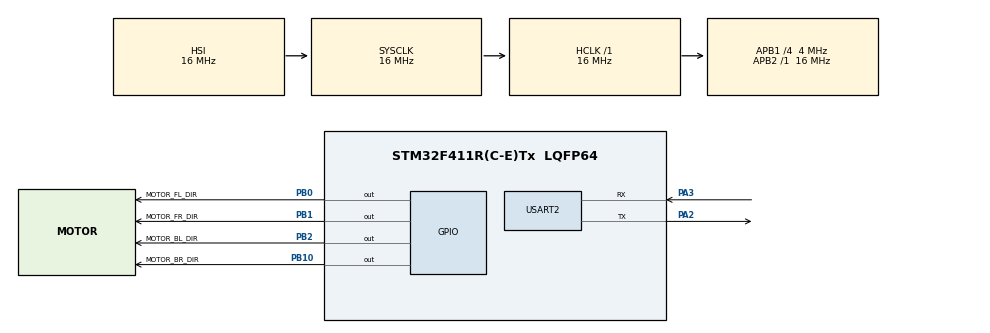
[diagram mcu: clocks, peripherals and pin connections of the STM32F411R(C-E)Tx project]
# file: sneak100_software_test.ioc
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Mcu.Family=STM32F4
RCC.CortexFreq_Value=16000000
PB0.GPIO_Label=MOTOR_FL_DIR
RCC.APB1CLKDivider=RCC_HCLK_DIV4
ProjectManager.StackSize=0x400
PA13.Signal=SYS_JTMS-SWDIO
PA3.Mode=Asynchronous
ProjectManager.TargetToolchain=STM32CubeIDE
PB10.GPIO_Label=MOTOR_BR_DIR
RCC.HCLKFreq_Value=16000000
RCC.APB2TimFreq_Value=16000000
RCC.LSE_VALUE=32768
RCC.AHBFreq_Value=16000000
PB10.Signal=GPIO_Output
RCC.HSE_VALUE=16000000
PB2.Signal=GPIO_Output
board=custom
RCC.VCOOutputFreq_Value=144000000
RCC.APB2Freq_Value=16000000
PA14.Mode=Serial_Wire
PB1.GPIO_Label=MOTOR_FR_DIR
PA13.Mode=Serial_Wire
Mcu.Name=STM32F411R(C-E)Tx
PA2.Signal=USART2_TX
RCC.48MHZClocksFreq_Value=48000000
RCC.SYSCLKFreq_VALUE=16000000
Mcu.Package=LQFP64
PB1.Signal=GPIO_Output
USART2.VirtualMode=VM_ASYNC
PA14.Signal=SYS_JTCK-SWCLK
PB2.GPIO_Label=MOTOR_BL_DIR
ProjectManager.HeapSize=0x200
RCC.HSI_VALUE=16000000
RCC.PLLQ=3
NVIC.PriorityGroup=NVIC_PRIORITYGROUP_4
RCC.PLLM=8
RCC.PLLN=72
RCC.APB1TimFreq_Value=8000000
PA2.Mode=Asynchronous
RCC.APB1Freq_Value=4000000
PB0.Signal=GPIO_Output
PA3.Signal=USART2_RX

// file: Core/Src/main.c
/* USER CODE BEGIN Header */
/**
  ******************************************************************************
  * @file           : main.c
  * @brief          : Main program body
  ******************************************************************************
  * @attention
  *
  * <h2><center>&copy; Copyright (c) 2021 STMicroelectronics.
  * All rights reserved.</center></h2>
  *
  * This software component is licensed by ST under BSD 3-Clause license,
  * the "License"; You may not use this file except in compliance with the
  * License. You may obtain a copy of the License at:
  *                        opensource.org/licenses/BSD-3-Clause
  *
  ******************************************************************************
  */
/* USER CODE END Header */
#include "main.h"
#include "usart.h"
#include "gpio.h"

/* USER CODE BEGIN Includes */
//#include "pid.h"

#include <stdio.h>
#include <string.h>
/* USER CODE END Includes */

void SystemClock_Config(void);
/* USER CODE BEGIN PFP */

int __io_putchar(int ch) {

    HAL_UART_Transmit(&huart2, (uint8_t*)&ch, 1, HAL_MAX_DELAY);

    return 1;
}

/* USER CODE END PFP */

int main(void)
{

  /* MCU Configuration--------------------------------------------------------*/

  /* Reset of all peripherals, Initializes the Flash interface and the Systick. */
  HAL_Init();

  /* Configure the system clock */
  SystemClock_Config();

  /* Initialize all configured peripherals */
  MX_GPIO_Init();
  MX_USART2_UART_Init();

  /* Infinite loop */
  /* USER CODE BEGIN WHILE */

  //PID_StructTypedef pid;

  //pid.us_timer = &htim2;

  while(1) {

	  printf("Hello world!\n");

	  HAL_Delay(100);

    /* USER CODE END WHILE */

  }
}

void SystemClock_Config(void)
{
  RCC_OscInitTypeDef RCC_OscInitStruct = {0};
  RCC_ClkInitTypeDef RCC_ClkInitStruct = {0};

  /** Configure the main internal regulator output voltage
  */
  __HAL_RCC_PWR_CLK_ENABLE();
  __HAL_PWR_VOLTAGESCALING_CONFIG(PWR_REGULATOR_VOLTAGE_SCALE1);
  /** Initializes the RCC Oscillators according to the specified parameters
  * in the RCC_OscInitTypeDef structure.
  */
  RCC_OscInitStruct.OscillatorType = RCC_OSCILLATORTYPE_HSI;
  RCC_OscInitStruct.HSIState = RCC_HSI_ON;
  RCC_OscInitStruct.HSICalibrationValue = RCC_HSICALIBRATION_DEFAULT;
  RCC_OscInitStruct.PLL.PLLState = RCC_PLL_NONE;
  if (HAL_RCC_OscConfig(&RCC_OscInitStruct) != HAL_OK)
  {
    Error_Handler();
  }
  /** Initializes the CPU, AHB and APB buses clocks
  */
  RCC_ClkInitStruct.ClockType = RCC_CLOCKTYPE_HCLK|RCC_CLOCKTYPE_SYSCLK
                              |RCC_CLOCKTYPE_PCLK1|RCC_CLOCKTYPE_PCLK2;
  RCC_ClkInitStruct.SYSCLKSource = RCC_SYSCLKSOURCE_HSI;
  RCC_ClkInitStruct.AHBCLKDivider = RCC_SYSCLK_DIV1;
  RCC_ClkInitStruct.APB1CLKDivider = RCC_HCLK_DIV4;
  RCC_ClkInitStruct.APB2CLKDivider = RCC_HCLK_DIV1;

  if (HAL_RCC_ClockConfig(&RCC_ClkInitStruct, FLASH_LATENCY_0) != HAL_OK)
  {
    Error_Handler();
  }
}

void Error_Handler(void)
{
  __disable_irq();
  while (1)
  {
  }
}

/************************ (C) COPYRIGHT STMicroelectronics *****END OF FILE****/
